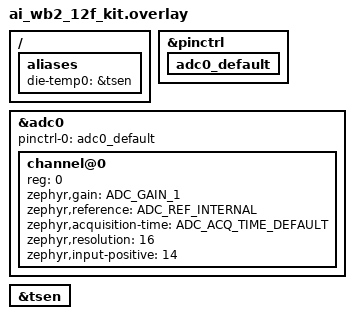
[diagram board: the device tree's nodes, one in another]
/*
 * Copyright The Zephyr Project Contributors
 * SPDX-License-Identifier: Apache-2.0
 */

#include <zephyr/dt-bindings/adc/adc.h>

&pinctrl {
	adc0_default: adc0_default {};
};

&adc0 {
	status = "okay";
	pinctrl-0 = <&adc0_default>;
	pinctrl-names = "default";

	channel@0 {
		reg = <0>;
		zephyr,gain = "ADC_GAIN_1";
		zephyr,reference = "ADC_REF_INTERNAL";
		zephyr,acquisition-time = <ADC_ACQ_TIME_DEFAULT>;
		zephyr,resolution = <16>;
		zephyr,input-positive = <14>;
	};
};

&tsen {
	status = "okay";
};

/ {
	aliases {
		die-temp0 = &tsen;
	};
};
